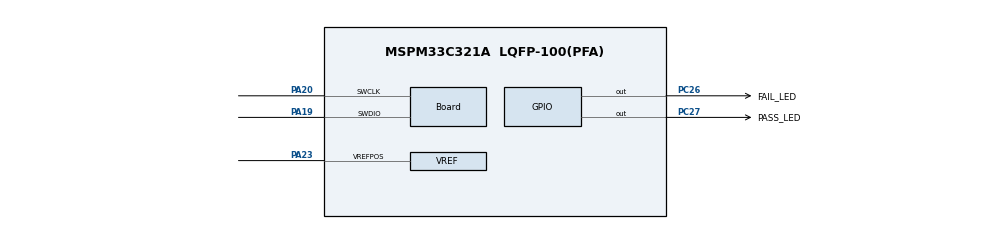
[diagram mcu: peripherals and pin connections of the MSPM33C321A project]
//@cliArgs --device "MSPM33C321A" --package "LQFP-100(PFA)" --part "Default"
//@v2CliArgs --device "MSPM33C321A" --package "LQFP-100(PFA)"
// @cliArgs --board /ti/boards/LP_MSPM33C321A --rtos nortos

/**
 * Import the modules used in this configuration.
 */
const Board         = scripting.addModule("/ti/driverlib/Board");
const COMP          = scripting.addModule("/ti/driverlib/COMP", {}, false);
const COMP1         = COMP.addInstance();
const GPIO          = scripting.addModule("/ti/driverlib/GPIO", {}, false);
const GPIO1         = GPIO.addInstance();
const SYSCTL        = scripting.addModule("/ti/driverlib/SYSCTL");
const VREF          = scripting.addModule("/ti/driverlib/VREF");
const ProjectConfig = scripting.addModule("/ti/project_config/ProjectConfig");

/**
 * Write custom configuration values to the imported modules.
 */
Board.InitPriority8               = "/ti/driverlib/VREF";
Board.peripheral.$assign          = "DEBUGSS";
Board.peripheral.swclkPin.$assign = "PA20";
Board.peripheral.swdioPin.$assign = "PA19";

COMP1.$name                          = "COMP_0";
COMP1.channelEnable                  = ["NEG","POS"];
COMP1.hysteresis                     = "DL_COMP_HYSTERESIS_20";
COMP1.enableOutputFilter             = true;
COMP1.selectOutputFilter             = "DL_COMP_FILTER_DELAY_1200";
COMP1.outputEnable                   = true;
COMP1.compPinPos0Config.$name        = "ti_driverlib_gpio_GPIOPinGeneric1";
COMP1.compPinNeg0Config.$name        = "ti_driverlib_gpio_GPIOPinGeneric2";
COMP1.peripheral.$assign             = "COMP0";
COMP1.peripheral.compPinOut.$assign  = "PA11";
COMP1.peripheral.compPinPos0.$assign = "PA26";
COMP1.peripheral.compPinNeg0.$assign = "PA27";
COMP1.compPinOutConfig.$name         = "ti_driverlib_gpio_GPIOPinGeneric3";

GPIO1.$name                               = "GPIO_LEDS";
GPIO1.associatedPins.create(2);
GPIO1.associatedPins[0].$name             = "PASS_LED";
GPIO1.associatedPins[0].launchPadShortcut = "LED2GreenEn";
GPIO1.associatedPins[0].pin.$assign       = "PC27";
GPIO1.associatedPins[1].$name             = "FAIL_LED";
GPIO1.associatedPins[1].launchPadShortcut = "LED2RedEn";
GPIO1.associatedPins[1].pin.$assign       = "PC26";

SYSCTL.peripheral.$assign = "SYSCTL";

VREF.basicMode                     = "DL_VREF_ENABLE_ENABLE";
VREF.basicIntVolt                  = "DL_VREF_BUFCONFIG_OUTPUT_1_4V";
VREF.peripheral.$assign            = "VREF";
VREF.peripheral.vrefPosPin.$assign = "PA23";
VREF.vrefPosPinConfig.$name        = "ti_driverlib_gpio_GPIOPinGeneric0";

ProjectConfig.migrationCondition = true;
ProjectConfig.genLinker          = true;
ProjectConfig.genStartup         = true;
ProjectConfig.genOpts            = true;
ProjectConfig.genLibs            = true;
